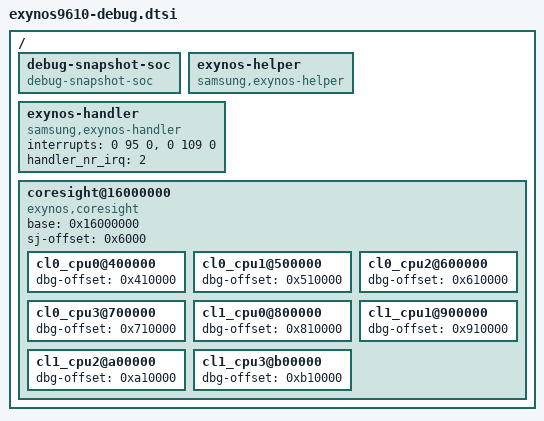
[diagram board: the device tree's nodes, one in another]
/*
 * SAMSUNG EXYNOS9820 SoC device tree source
 *
 * Copyright (c) 2018 Samsung Electronics Co., Ltd.
 *		http://www.samsung.com
 *
 * SAMSUNG EXYNOS9820 SoC device nodes are listed in this file.
 * EXYNOS9820 based board files can include this file and provide
 * values for board specfic bindings.
 *
 * This program is free software; you can redistribute it and/or modify
 * it under the terms of the GNU General Public License version 2 as
 * published by the Free Software Foundation.
 */

#include <dt-bindings/clock/exynos9610.h>

/ {
	debug-snapshot-soc {
		compatible = "debug-snapshot-soc";
		#address-cells = <1>;
		#size-cells = <1>;

		//use_multistage_wdt_irq = <497>;
		/* -----------<< Example >>-------------------
		dump-info@0x0 {
			sfr-dump-list = "sfr-dump-cmu-peris", "sfr-dump-cmu-abox";
			sfr-dump-cmu-peris {
				reg = <0x10010100 0x4000>;
				addr = <0x10010100 0x10010104 0x10010108 0xFFFFFFFF>;
			};

			sfr-dump-cmu-abox {
				reg = <0x103e0000 0x4000>;
				addr = <0x103e0100 0x103e0104 0x103e0108 0xFFFFFFFF>;
			};
		};
		*/
	};

	exynos-helper {
		compatible = "samsung,exynos-helper";
	};

	exynos-handler {
		compatible = "samsung,exynos-handler";
		interrupts =	<0 95 0>,	/* INTREQ__CPUCL0_nINTERRIRQ */
				<0 109 0>;	/* INTREQ__CPUCL1_nECCERRIRQ */
		handler_nr_irq = <2>;
	};

        coresight@16000000 {
		compatible = "exynos,coresight";
		base = <0x16000000>;
		sj-offset = <0x6000>;
		cl0_cpu0@400000 {
		        device_type = "cs";
			dbg-offset = <0x410000>;
		};
		cl0_cpu1@500000 {
		        device_type = "cs";
			dbg-offset = <0x510000>;
		};
		cl0_cpu2@600000 {
		        device_type = "cs";
			dbg-offset = <0x610000>;
		};
		cl0_cpu3@700000 {
		        device_type = "cs";
			dbg-offset = <0x710000>;
		};
		cl1_cpu0@800000 {
		        device_type = "cs";
			dbg-offset = <0x810000>;
		};
		cl1_cpu1@900000 {
		        device_type = "cs";
			dbg-offset = <0x910000>;
		};
		cl1_cpu2@a00000 {
		        device_type = "cs";
			dbg-offset = <0xa10000>;
		};
		cl1_cpu3@b00000 {
		        device_type = "cs";
			dbg-offset = <0xb10000>;
		};
	};
};
